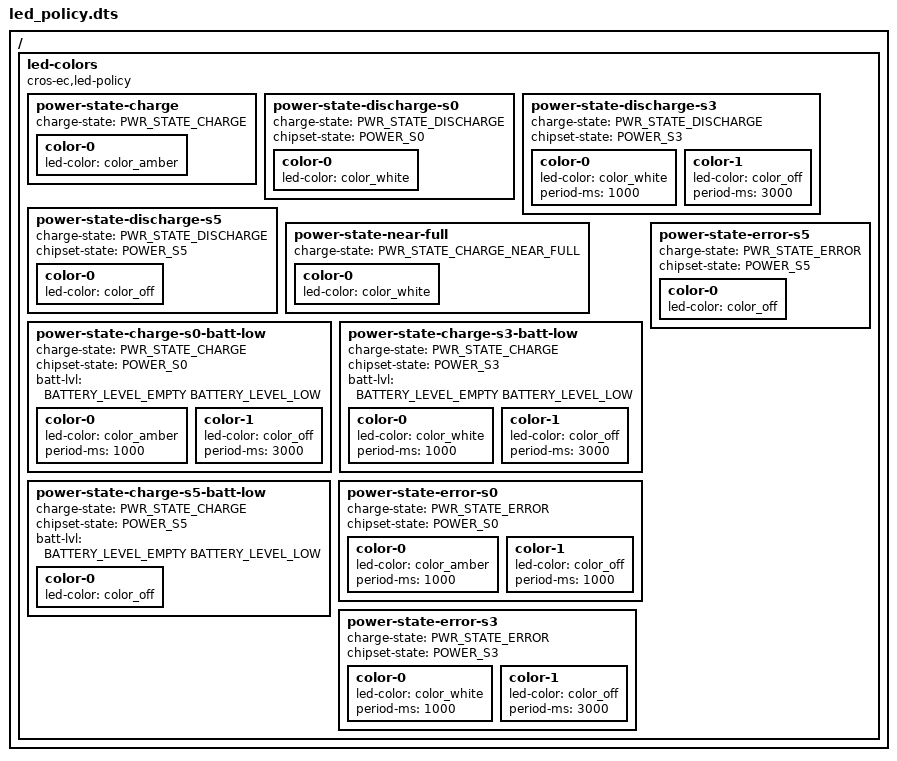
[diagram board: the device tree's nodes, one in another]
#include <dt-bindings/battery.h>

/ {
	led-colors {
		compatible = "cros-ec,led-policy";

		power-state-charge {
			charge-state = "PWR_STATE_CHARGE";

			color-0 {
				led-color = <&color_amber>;
			};
		};

		power-state-discharge-s0 {
			charge-state = "PWR_STATE_DISCHARGE";
			chipset-state = "POWER_S0";

			color-0 {
				led-color = <&color_white>;
			};
		};

		power-state-discharge-s3 {
			charge-state = "PWR_STATE_DISCHARGE";
			chipset-state = "POWER_S3";

			/* White 1 sec, off 3 sec */
			color-0 {
				led-color = <&color_white>;
				period-ms = <1000>;
			};
			color-1 {
				led-color = <&color_off>;
				period-ms = <3000>;
			};
		};

		power-state-discharge-s5 {
			charge-state = "PWR_STATE_DISCHARGE";
			chipset-state = "POWER_S5";

			color-0 {
				led-color = <&color_off>;
			};
		};

		power-state-near-full {
			charge-state = "PWR_STATE_CHARGE_NEAR_FULL";

			color-0 {
				led-color = <&color_white>;
			};
		};

		power-state-charge-s0-batt-low {
			charge-state = "PWR_STATE_CHARGE";
			chipset-state = "POWER_S0";
			/* Battery percent range (>= Empty, <= Low) */
			batt-lvl = <BATTERY_LEVEL_EMPTY BATTERY_LEVEL_LOW>;

			/* Amber 1 sec, off 3 sec */
			color-0 {
				led-color = <&color_amber>;
				period-ms = <1000>;
			};
			color-1 {
				led-color = <&color_off>;
				period-ms = <3000>;
			};
		};

		power-state-charge-s3-batt-low {
			charge-state = "PWR_STATE_CHARGE";
			chipset-state = "POWER_S3";
			/* Battery percent range (>= Empty, <= Low) */
			batt-lvl = <BATTERY_LEVEL_EMPTY BATTERY_LEVEL_LOW>;

			/* White 1 sec, off 3 sec */
			color-0 {
				led-color = <&color_white>;
				period-ms = <1000>;
			};
			color-1 {
				led-color = <&color_off>;
				period-ms = <3000>;
			};
		};

		power-state-charge-s5-batt-low {
			charge-state = "PWR_STATE_CHARGE";
			chipset-state = "POWER_S5";
			/* Battery percent range (>= Empty, <= Low) */
			batt-lvl = <BATTERY_LEVEL_EMPTY BATTERY_LEVEL_LOW>;

			color-0 {
				led-color = <&color_off>;
			};
		};

		power-state-error-s0 {
			charge-state = "PWR_STATE_ERROR";
			chipset-state = "POWER_S0";
			/* Amber 1 sec, off 1 sec */
			color-0 {
				led-color = <&color_amber>;
				period-ms = <1000>;
			};
			color-1 {
				led-color = <&color_off>;
				period-ms = <1000>;
			};
		};

		power-state-error-s3 {
			charge-state = "PWR_STATE_ERROR";
			chipset-state = "POWER_S3";
			/* White 1 sec, off 3 sec */
			color-0 {
				led-color = <&color_white>;
				period-ms = <1000>;
			};
			color-1 {
				led-color = <&color_off>;
				period-ms = <3000>;
			};
		};

		power-state-error-s5 {
			charge-state = "PWR_STATE_ERROR";
			chipset-state = "POWER_S5";

			color-0 {
				led-color = <&color_off>;
			};
		};
	};
};
